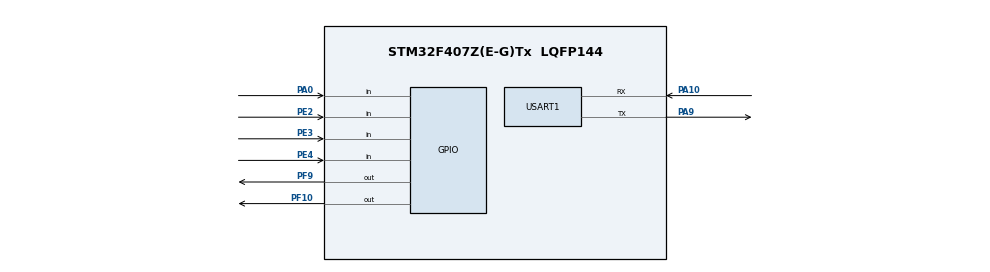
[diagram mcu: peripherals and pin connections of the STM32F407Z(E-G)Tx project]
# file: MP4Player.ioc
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FREERTOS.Tasks01=defaultTask,24,128,StartDefaultTask,Default,NULL,Dynamic,NULL,NULL
Mcu.Family=STM32F4
Mcu.Name=STM32F407Z(E-G)Tx
Mcu.Package=LQFP144
NVIC.PriorityGroup=NVIC_PRIORITYGROUP_4
NVIC.USART1_IRQn=true\:3\:0\:true\:false\:true\:false\:true\:true
PA0-WKUP.Signal=GPIO_Input
PA10.Mode=Asynchronous
PA10.Signal=USART1_RX
PA9.Mode=Asynchronous
PA9.Signal=USART1_TX
PC14-OSC32_IN.Mode=LSE-External-Oscillator
PC14-OSC32_IN.Signal=RCC_OSC32_IN
PC15-OSC32_OUT.Mode=LSE-External-Oscillator
PC15-OSC32_OUT.Signal=RCC_OSC32_OUT
PE2.Signal=GPIO_Input
PE3.Signal=GPIO_Input
PE4.Signal=GPIO_Input
PF10.Signal=GPIO_Output
PF9.Signal=GPIO_Output
PH0-OSC_IN.Mode=HSE-External-Oscillator
PH0-OSC_IN.Signal=RCC_OSC_IN
PH1-OSC_OUT.Mode=HSE-External-Oscillator
PH1-OSC_OUT.Signal=RCC_OSC_OUT
ProjectManager.HeapSize=0x200
ProjectManager.StackSize=0x400
ProjectManager.TargetToolchain=MDK-ARM V5.27
RCC.48MHZClocksFreq_Value=84000000
RCC.AHBFreq_Value=168000000
RCC.APB1CLKDivider=RCC_HCLK_DIV4
RCC.APB1Freq_Value=42000000
RCC.APB1TimFreq_Value=84000000
RCC.APB2CLKDivider=RCC_HCLK_DIV2
RCC.APB2Freq_Value=84000000
RCC.APB2TimFreq_Value=168000000
RCC.CortexFreq_Value=168000000
RCC.HCLKFreq_Value=168000000
RCC.HSE_VALUE=8000000
RCC.HSI_VALUE=16000000
RCC.PLLM=4
RCC.PLLN=168
RCC.PLLSourceVirtual=RCC_PLLSOURCE_HSE
RCC.SYSCLKFreq_VALUE=168000000
RCC.SYSCLKSource=RCC_SYSCLKSOURCE_PLLCLK
RCC.VCOOutputFreq_Value=336000000
USART1.VirtualMode=VM_ASYNC
VP_FREERTOS_VS_CMSIS_V2.Mode=CMSIS_V2
board=custom

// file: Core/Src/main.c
/* USER CODE BEGIN Header */
/**
  ******************************************************************************
  * @file           : main.c
  * @brief          : Main program body
  ******************************************************************************
  * @attention
  *
  * <h2><center>&copy; Copyright (c) 2020 STMicroelectronics.
  * All rights reserved.</center></h2>
  *
  * This software component is licensed by ST under BSD 3-Clause license,
  * the "License"; You may not use this file except in compliance with the
  * License. You may obtain a copy of the License at:
  *                        opensource.org/licenses/BSD-3-Clause
  *
  ******************************************************************************
  */
/* USER CODE END Header */
#include "main.h"
#include "cmsis_os.h"
#include "usart.h"
#include "gpio.h"

/* USER CODE BEGIN Includes */
#include "Include.h"
/* USER CODE END Includes */

/* USER CODE BEGIN PV */

#define START_TASK_PRIO		1 //���ȼ�
#define START_STK_SIZE 		128  //��ջ��С
TaskHandle_t StartTask_Handler;//���
void start_task(void *pvParameters);//����

/* USER CODE END PV */

void SystemClock_Config(void);
void MX_FREERTOS_Init(void);

int main(void)
{

  /* MCU Configuration--------------------------------------------------------*/

  /* Reset of all peripherals, Initializes the Flash interface and the Systick. */

  LL_APB2_GRP1_EnableClock(LL_APB2_GRP1_PERIPH_SYSCFG);
  LL_APB1_GRP1_EnableClock(LL_APB1_GRP1_PERIPH_PWR);

  NVIC_SetPriorityGrouping(NVIC_PRIORITYGROUP_4);

  /* System interrupt init*/

  /* Configure the system clock */
  SystemClock_Config();

  /* Initialize all configured peripherals */
  MX_GPIO_Init();
  MX_USART1_UART_Init();
  /* USER CODE BEGIN 2 */
	user_usartInit();
  /* USER CODE END 2 */

  /* Init scheduler */
  osKernelInitialize();  /* Call init function for freertos objects (in freertos.c) */
  MX_FREERTOS_Init();
  /* Start scheduler */
//  osKernelStart();

  /* We should never get here as control is now taken by the scheduler */
  /* Infinite loop */
  /* USER CODE BEGIN WHILE */
	xTaskCreate(start_task,"start_task",START_STK_SIZE,NULL,START_TASK_PRIO,&StartTask_Handler);
  vTaskStartScheduler();         //Start scheduler
	while (1)
  {
    /* USER CODE END WHILE */

  }
}

void SystemClock_Config(void)
 {
  LL_FLASH_SetLatency(LL_FLASH_LATENCY_5);
  while(LL_FLASH_GetLatency()!= LL_FLASH_LATENCY_5)
  {
  }
  LL_PWR_SetRegulVoltageScaling(LL_PWR_REGU_VOLTAGE_SCALE1);
  LL_RCC_HSE_Enable();

   /* Wait till HSE is ready */
  while(LL_RCC_HSE_IsReady() != 1)
  {

  }
  LL_RCC_PLL_ConfigDomain_SYS(LL_RCC_PLLSOURCE_HSE, LL_RCC_PLLM_DIV_4, 168, LL_RCC_PLLP_DIV_2);
  LL_RCC_PLL_Enable();

   /* Wait till PLL is ready */
  while(LL_RCC_PLL_IsReady() != 1)
  {

  }
  LL_RCC_SetAHBPrescaler(LL_RCC_SYSCLK_DIV_1);
  LL_RCC_SetAPB1Prescaler(LL_RCC_APB1_DIV_4);
  LL_RCC_SetAPB2Prescaler(LL_RCC_APB2_DIV_2);
  LL_RCC_SetSysClkSource(LL_RCC_SYS_CLKSOURCE_PLL);

   /* Wait till System clock is ready */
  while(LL_RCC_GetSysClkSource() != LL_RCC_SYS_CLKSOURCE_STATUS_PLL)
  {

  }
  LL_Init1msTick(168000000);
  LL_SetSystemCoreClock(168000000);
}

/* USER CODE BEGIN 4 */
void start_task(void *pvParameters)
{
	taskENTER_CRITICAL();

	Led_Init();
	Key_Init();

	vTaskDelete(StartTask_Handler); //删除�?始任�?
  taskEXIT_CRITICAL();            //�?出临界区
}

/* USER CODE END 4 */

void Error_Handler(void)
{
}

/************************ (C) COPYRIGHT STMicroelectronics *****END OF FILE****/
